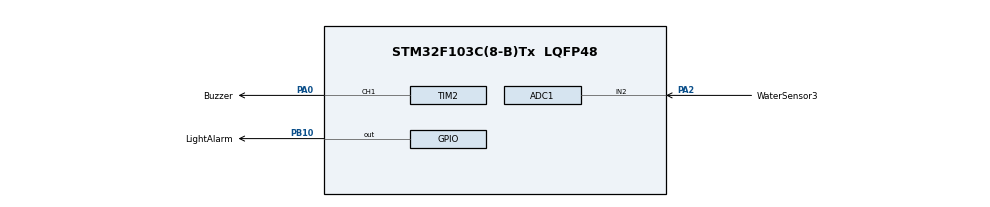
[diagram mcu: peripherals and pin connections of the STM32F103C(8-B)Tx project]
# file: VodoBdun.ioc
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ADC1.Channel-12\#ChannelRegularConversion=ADC_CHANNEL_2
ADC1.ContinuousConvMode=DISABLE
ADC1.DataAlign=ADC_DATAALIGN_RIGHT
ADC1.DiscontinuousConvMode=DISABLE
ADC1.EnableAnalogWatchDog=false
ADC1.EnableRegularConversion=ENABLE
ADC1.ExternalTrigConv=ADC_SOFTWARE_START
ADC1.InjNumberOfConversion=0
ADC1.NbrOfConversion=1
ADC1.NbrOfConversionFlag=1
ADC1.Rank-12\#ChannelRegularConversion=1
ADC1.SamplingTime-12\#ChannelRegularConversion=ADC_SAMPLETIME_1CYCLE_5
ADC1.ScanConvMode=ADC_SCAN_DISABLE
ADC1.master=1
Dma.ADC1.0.Direction=DMA_PERIPH_TO_MEMORY
Dma.ADC1.0.Instance=DMA1_Channel1
Dma.ADC1.0.MemDataAlignment=DMA_MDATAALIGN_HALFWORD
Dma.ADC1.0.MemInc=DMA_MINC_ENABLE
Dma.ADC1.0.Mode=DMA_NORMAL
Dma.ADC1.0.PeriphDataAlignment=DMA_PDATAALIGN_HALFWORD
Dma.ADC1.0.PeriphInc=DMA_PINC_DISABLE
Dma.ADC1.0.Priority=DMA_PRIORITY_LOW
Dma.Request0=ADC1
FREERTOS.Events01=EventAlarmRun,Static,EventAlarmRunControlBlock
FREERTOS.Tasks01=TaskSensors,24,128,StartTaskSensors,Default,NULL,Static,TaskSensorsBuffer,TaskSensorsControlBlock;TaskMain,8,128,StartTaskMain,Default,NULL,Static,TaskMainBuffer,TaskMainControlBlock;TaskAlarm,8,128,StartTaskAlarm,Default,NULL,Static,TaskAlarmBuffer,TaskAlarmControlBlock
Mcu.Family=STM32F1
Mcu.Name=STM32F103C(8-B)Tx
Mcu.Package=LQFP48
NVIC.ADC1_2_IRQn=true\:5\:0\:false\:false\:true\:true\:true\:true\:true
NVIC.DMA1_Channel1_IRQn=true\:5\:0\:false\:false\:true\:true\:false\:true\:true
NVIC.PriorityGroup=NVIC_PRIORITYGROUP_4
NVIC.TIM1_UP_IRQn=true\:0\:0\:false\:false\:true\:false\:false\:true\:true
NVIC.TimeBase=TIM1_UP_IRQn
NVIC.TimeBaseIP=TIM1
PA0-WKUP.GPIO_Label=Buzzer
PA0-WKUP.Signal=S_TIM2_CH1_ETR
PA13.Mode=Serial_Wire
PA13.Signal=SYS_JTMS-SWDIO
PA14.Mode=Serial_Wire
PA14.Signal=SYS_JTCK-SWCLK
PA2.GPIO_Label=WaterSensor3
PA2.Signal=ADCx_IN2
PB10.GPIO_Label=LightAlarm
PB10.Signal=GPIO_Output
PD0-OSC_IN.Mode=HSE-External-Oscillator
PD0-OSC_IN.Signal=RCC_OSC_IN
PD1-OSC_OUT.Mode=HSE-External-Oscillator
PD1-OSC_OUT.Signal=RCC_OSC_OUT
ProjectManager.HeapSize=0x200
ProjectManager.StackSize=0x400
ProjectManager.TargetToolchain=EWARM V8.32
RCC.APB1Freq_Value=8000000
RCC.APB2Freq_Value=8000000
SH.ADCx_IN2.0=ADC1_IN2,IN2
SH.S_TIM2_CH1_ETR.0=TIM2_CH1,PWM Generation1 CH1
TIM2.Channel-PWM\ Generation1\ CH1=TIM_CHANNEL_1
TIM2.Prescaler=100
VP_FREERTOS_VS_CMSIS_V2.Mode=CMSIS_V2
VP_RTC_VS_RTC_Activate.Mode=RTC_Enabled
VP_RTC_VS_RTC_Calendar.Mode=RTC_Calendar
VP_SYS_VS_tim1.Mode=TIM1
VP_TIM2_VS_ClockSourceINT.Mode=Internal
board=Aquastop

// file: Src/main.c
/* USER CODE BEGIN Header */
/**
  ******************************************************************************
  * @file           : main.c
  * @brief          : Main program body
  ******************************************************************************
  * @attention
  *
  * Copyright (c) 2023 STMicroelectronics.
  * All rights reserved.
  *
  * This software is licensed under terms that can be found in the LICENSE file
  * in the root directory of this software component.
  * If no LICENSE file comes with this software, it is provided AS-IS.
  *
  ******************************************************************************
  */
/* USER CODE END Header */
#include "main.h"
#include "cmsis_os.h"

/* USER CODE BEGIN Includes */
#include "GlobalHeader.h"
/* USER CODE END Includes */

typedef StaticTask_t osStaticThreadDef_t;
typedef StaticEventGroup_t osStaticEventGroupDef_t;

ADC_HandleTypeDef hadc1;
DMA_HandleTypeDef hdma_adc1;

RTC_HandleTypeDef hrtc;

TIM_HandleTypeDef htim2;

/* Definitions for TaskSensors */
osThreadId_t TaskSensorsHandle;
uint32_t TaskSensorsBuffer[ 128 ];
osStaticThreadDef_t TaskSensorsControlBlock;
const osThreadAttr_t TaskSensors_attributes = {
  .name = "TaskSensors",
  .cb_mem = &TaskSensorsControlBlock,
  .cb_size = sizeof(TaskSensorsControlBlock),
  .stack_mem = &TaskSensorsBuffer[0],
  .stack_size = sizeof(TaskSensorsBuffer),
  .priority = (osPriority_t) osPriorityNormal,
};
/* Definitions for TaskMain */
osThreadId_t TaskMainHandle;
uint32_t TaskMainBuffer[ 128 ];
osStaticThreadDef_t TaskMainControlBlock;
const osThreadAttr_t TaskMain_attributes = {
  .name = "TaskMain",
  .cb_mem = &TaskMainControlBlock,
  .cb_size = sizeof(TaskMainControlBlock),
  .stack_mem = &TaskMainBuffer[0],
  .stack_size = sizeof(TaskMainBuffer),
  .priority = (osPriority_t) osPriorityLow,
};
/* Definitions for TaskAlarm */
osThreadId_t TaskAlarmHandle;
uint32_t TaskAlarmBuffer[ 128 ];
osStaticThreadDef_t TaskAlarmControlBlock;
const osThreadAttr_t TaskAlarm_attributes = {
  .name = "TaskAlarm",
  .cb_mem = &TaskAlarmControlBlock,
  .cb_size = sizeof(TaskAlarmControlBlock),
  .stack_mem = &TaskAlarmBuffer[0],
  .stack_size = sizeof(TaskAlarmBuffer),
  .priority = (osPriority_t) osPriorityLow,
};
/* Definitions for EventAlarmRun */
osEventFlagsId_t EventAlarmRunHandle;
osStaticEventGroupDef_t EventAlarmRunControlBlock;
const osEventFlagsAttr_t EventAlarmRun_attributes = {
  .name = "EventAlarmRun",
  .cb_mem = &EventAlarmRunControlBlock,
  .cb_size = sizeof(EventAlarmRunControlBlock),
};

void SystemClock_Config(void);
static void MX_GPIO_Init(void);
static void MX_DMA_Init(void);
static void MX_ADC1_Init(void);
static void MX_TIM2_Init(void);
static void MX_RTC_Init(void);
void StartTaskSensors(void *argument);
void StartTaskMain(void *argument);
void StartTaskAlarm(void *argument);

/* USER CODE BEGIN 0 */
extern uint16_t adc;
/* USER CODE END 0 */

int main(void)
{

  /* MCU Configuration--------------------------------------------------------*/

  /* Reset of all peripherals, Initializes the Flash interface and the Systick. */
  HAL_Init();

  /* Configure the system clock */
  SystemClock_Config();

  /* Initialize all configured peripherals */
  MX_GPIO_Init();
  MX_DMA_Init();
  MX_ADC1_Init();
  MX_TIM2_Init();
  MX_RTC_Init();

  /* Init scheduler */
  osKernelInitialize();

  /* Create the thread(s) */
  /* creation of TaskSensors */
  TaskSensorsHandle = osThreadNew(StartTaskSensors, NULL, &TaskSensors_attributes);

  /* creation of TaskMain */
  TaskMainHandle = osThreadNew(StartTaskMain, NULL, &TaskMain_attributes);

  /* creation of TaskAlarm */
  TaskAlarmHandle = osThreadNew(StartTaskAlarm, NULL, &TaskAlarm_attributes);

  /* Create the event(s) */
  /* creation of EventAlarmRun */
  EventAlarmRunHandle = osEventFlagsNew(&EventAlarmRun_attributes);

  /* Start scheduler */
  osKernelStart();
  /* We should never get here as control is now taken by the scheduler */
  /* Infinite loop */
  while (1)
  {

  }
}

void SystemClock_Config(void)
{
  RCC_OscInitTypeDef RCC_OscInitStruct = {0};
  RCC_ClkInitTypeDef RCC_ClkInitStruct = {0};
  RCC_PeriphCLKInitTypeDef PeriphClkInit = {0};

  /** Initializes the RCC Oscillators according to the specified parameters
  * in the RCC_OscInitTypeDef structure.
  */
  RCC_OscInitStruct.OscillatorType = RCC_OSCILLATORTYPE_HSI|RCC_OSCILLATORTYPE_LSI;
  RCC_OscInitStruct.HSIState = RCC_HSI_ON;
  RCC_OscInitStruct.HSICalibrationValue = RCC_HSICALIBRATION_DEFAULT;
  RCC_OscInitStruct.LSIState = RCC_LSI_ON;
  RCC_OscInitStruct.PLL.PLLState = RCC_PLL_NONE;
  if (HAL_RCC_OscConfig(&RCC_OscInitStruct) != HAL_OK)
  {
    Error_Handler();
  }

  /** Initializes the CPU, AHB and APB buses clocks
  */
  RCC_ClkInitStruct.ClockType = RCC_CLOCKTYPE_HCLK|RCC_CLOCKTYPE_SYSCLK
                              |RCC_CLOCKTYPE_PCLK1|RCC_CLOCKTYPE_PCLK2;
  RCC_ClkInitStruct.SYSCLKSource = RCC_SYSCLKSOURCE_HSI;
  RCC_ClkInitStruct.AHBCLKDivider = RCC_SYSCLK_DIV1;
  RCC_ClkInitStruct.APB1CLKDivider = RCC_HCLK_DIV1;
  RCC_ClkInitStruct.APB2CLKDivider = RCC_HCLK_DIV1;

  if (HAL_RCC_ClockConfig(&RCC_ClkInitStruct, FLASH_LATENCY_0) != HAL_OK)
  {
    Error_Handler();
  }
  PeriphClkInit.PeriphClockSelection = RCC_PERIPHCLK_RTC|RCC_PERIPHCLK_ADC;
  PeriphClkInit.RTCClockSelection = RCC_RTCCLKSOURCE_LSI;
  PeriphClkInit.AdcClockSelection = RCC_ADCPCLK2_DIV2;
  if (HAL_RCCEx_PeriphCLKConfig(&PeriphClkInit) != HAL_OK)
  {
    Error_Handler();
  }
}

static void MX_ADC1_Init(void)
{

  ADC_ChannelConfTypeDef sConfig = {0};

  /** Common config
  */
  hadc1.Instance = ADC1;
  hadc1.Init.ScanConvMode = ADC_SCAN_DISABLE;
  hadc1.Init.ContinuousConvMode = DISABLE;
  hadc1.Init.DiscontinuousConvMode = DISABLE;
  hadc1.Init.ExternalTrigConv = ADC_SOFTWARE_START;
  hadc1.Init.DataAlign = ADC_DATAALIGN_RIGHT;
  hadc1.Init.NbrOfConversion = 1;
  if (HAL_ADC_Init(&hadc1) != HAL_OK)
  {
    Error_Handler();
  }

  /** Configure Regular Channel
  */
  sConfig.Channel = ADC_CHANNEL_2;
  sConfig.Rank = ADC_REGULAR_RANK_1;
  sConfig.SamplingTime = ADC_SAMPLETIME_1CYCLE_5;
  if (HAL_ADC_ConfigChannel(&hadc1, &sConfig) != HAL_OK)
  {
    Error_Handler();
  }

}

static void MX_RTC_Init(void)
{

  RTC_TimeTypeDef sTime = {0};
  RTC_DateTypeDef DateToUpdate = {0};

  /** Initialize RTC Only
  */
  hrtc.Instance = RTC;
  hrtc.Init.AsynchPrediv = RTC_AUTO_1_SECOND;
  hrtc.Init.OutPut = RTC_OUTPUTSOURCE_ALARM;
  if (HAL_RTC_Init(&hrtc) != HAL_OK)
  {
    Error_Handler();
  }

  /** Initialize RTC and set the Time and Date
  */
  sTime.Hours = 0x0;
  sTime.Minutes = 0x0;
  sTime.Seconds = 0x0;

  if (HAL_RTC_SetTime(&hrtc, &sTime, RTC_FORMAT_BCD) != HAL_OK)
  {
    Error_Handler();
  }
  DateToUpdate.WeekDay = RTC_WEEKDAY_MONDAY;
  DateToUpdate.Month = RTC_MONTH_JANUARY;
  DateToUpdate.Date = 0x1;
  DateToUpdate.Year = 0x0;

  if (HAL_RTC_SetDate(&hrtc, &DateToUpdate, RTC_FORMAT_BCD) != HAL_OK)
  {
    Error_Handler();
  }

}

static void MX_TIM2_Init(void)
{

  TIM_ClockConfigTypeDef sClockSourceConfig = {0};
  TIM_MasterConfigTypeDef sMasterConfig = {0};
  TIM_OC_InitTypeDef sConfigOC = {0};

  htim2.Instance = TIM2;
  htim2.Init.Prescaler = 100;
  htim2.Init.CounterMode = TIM_COUNTERMODE_UP;
  htim2.Init.Period = 65535;
  htim2.Init.ClockDivision = TIM_CLOCKDIVISION_DIV1;
  htim2.Init.AutoReloadPreload = TIM_AUTORELOAD_PRELOAD_DISABLE;
  if (HAL_TIM_Base_Init(&htim2) != HAL_OK)
  {
    Error_Handler();
  }
  sClockSourceConfig.ClockSource = TIM_CLOCKSOURCE_INTERNAL;
  if (HAL_TIM_ConfigClockSource(&htim2, &sClockSourceConfig) != HAL_OK)
  {
    Error_Handler();
  }
  if (HAL_TIM_PWM_Init(&htim2) != HAL_OK)
  {
    Error_Handler();
  }
  sMasterConfig.MasterOutputTrigger = TIM_TRGO_RESET;
  sMasterConfig.MasterSlaveMode = TIM_MASTERSLAVEMODE_DISABLE;
  if (HAL_TIMEx_MasterConfigSynchronization(&htim2, &sMasterConfig) != HAL_OK)
  {
    Error_Handler();
  }
  sConfigOC.OCMode = TIM_OCMODE_PWM1;
  sConfigOC.Pulse = 0;
  sConfigOC.OCPolarity = TIM_OCPOLARITY_HIGH;
  sConfigOC.OCFastMode = TIM_OCFAST_DISABLE;
  if (HAL_TIM_PWM_ConfigChannel(&htim2, &sConfigOC, TIM_CHANNEL_1) != HAL_OK)
  {
    Error_Handler();
  }
  HAL_TIM_MspPostInit(&htim2);

}

static void MX_DMA_Init(void)
{

  /* DMA controller clock enable */
  __HAL_RCC_DMA1_CLK_ENABLE();

  /* DMA interrupt init */
  /* DMA1_Channel1_IRQn interrupt configuration */
  HAL_NVIC_SetPriority(DMA1_Channel1_IRQn, 5, 0);
  HAL_NVIC_EnableIRQ(DMA1_Channel1_IRQn);

}

static void MX_GPIO_Init(void)
{
  GPIO_InitTypeDef GPIO_InitStruct = {0};

  /* GPIO Ports Clock Enable */
  __HAL_RCC_GPIOD_CLK_ENABLE();
  __HAL_RCC_GPIOA_CLK_ENABLE();
  __HAL_RCC_GPIOB_CLK_ENABLE();

  /*Configure GPIO pin Output Level */
  HAL_GPIO_WritePin(LightAlarm_GPIO_Port, LightAlarm_Pin, GPIO_PIN_RESET);

  /*Configure GPIO pin : LightAlarm_Pin */
  GPIO_InitStruct.Pin = LightAlarm_Pin;
  GPIO_InitStruct.Mode = GPIO_MODE_OUTPUT_PP;
  GPIO_InitStruct.Pull = GPIO_NOPULL;
  GPIO_InitStruct.Speed = GPIO_SPEED_FREQ_LOW;
  HAL_GPIO_Init(LightAlarm_GPIO_Port, &GPIO_InitStruct);

}

void StartTaskSensors(void *argument)
{
  /* USER CODE BEGIN 5 */
	HAL_ADCEx_Calibration_Start(&hadc1);
	HAL_ADC_Start_DMA(&hadc1, (uint32_t*)&adc, 2);
  /* Infinite loop */
  for(;;)
  {
    SensorDrive();
    osDelay(1);
  }
  /* USER CODE END 5 */
}

void StartTaskMain(void *argument)
{
  for(;;)
  {
    osDelay(1);
  }
}

void StartTaskAlarm(void *argument)
{
  /* USER CODE BEGIN StartTaskAlarm */

//	TIM_BaseOptions.TIM_Period = 2 * BUZZER_VOLUME_MAX - 1;
//	TIM_BaseOptions.TIM_ClockDivision = TIM_CKD_DIV1;
//	TIM_BaseOptions.TIM_CounterMode = TIM_CounterMode_Up;
//	TIM_TimeBaseInit(TIM2, &TIM_BaseOptions);

  /* Infinite loop */
  for(;;)
  {

    osDelay(1);
  }
  /* USER CODE END StartTaskAlarm */
}

void HAL_TIM_PeriodElapsedCallback(TIM_HandleTypeDef *htim)
{
  if (htim->Instance == TIM1) {
    HAL_IncTick();
  }
}

void Error_Handler(void)
{
  __disable_irq();
  while (1)
  {
  }
}
